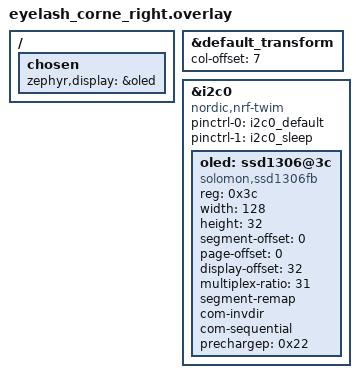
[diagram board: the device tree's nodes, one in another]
/*
*
* Copyright (c) 2024 The ZMK Contributors
* SPDX-License-Identifier: MIT
*
*/

#include "eyelash_corne.dtsi"
#include <behaviors/battery_history_request.dtsi>

&default_transform {
    col-offset = <7>;
};

&i2c0 {
    status = "okay";
    compatible = "nordic,nrf-twim";
    pinctrl-0 = <&i2c0_default>;
    pinctrl-1 = <&i2c0_sleep>;
    pinctrl-names = "default", "sleep";
    oled: ssd1306@3c {
        compatible = "solomon,ssd1306fb";
        reg = <0x3c>;
        width = <128>;
        height = <32>;
        segment-offset = <0>;
        page-offset = <0>;
        display-offset = <32>;
        multiplex-ratio = <31>;
        segment-remap;
        com-invdir;
        com-sequential;
        prechargep = <0x22>;
    };
};

/ {
    chosen {
        zephyr,display = &oled;
    };
};
